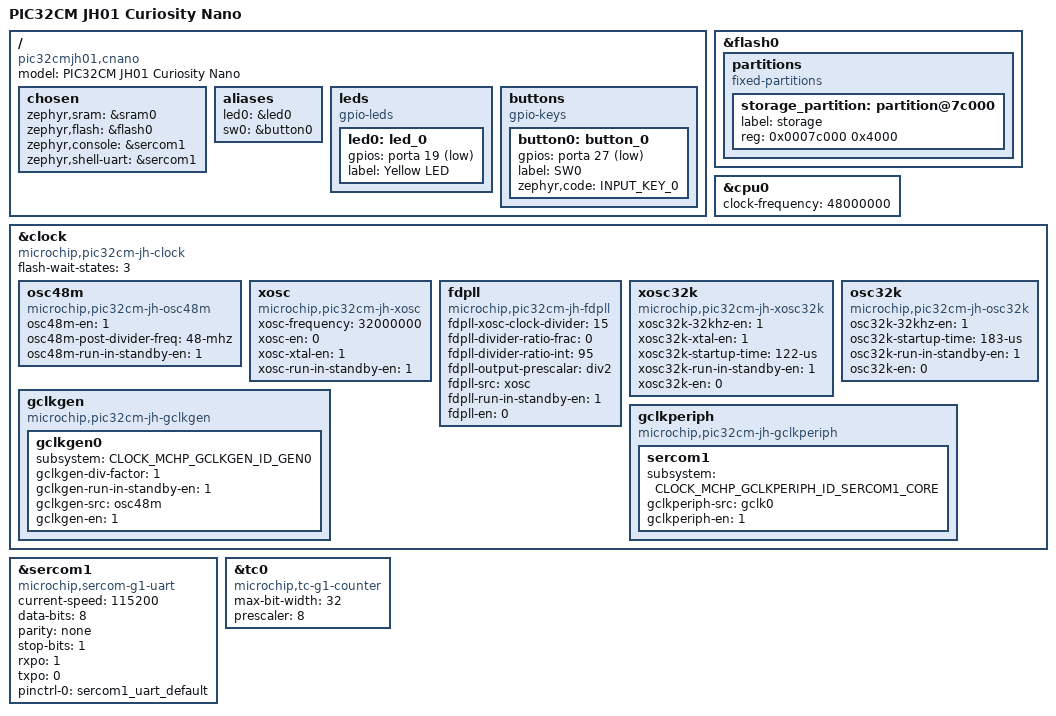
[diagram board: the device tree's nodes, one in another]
/*
 * Copyright (c) 2025-2026 Microchip Technology Inc.
 *
 * SPDX-License-Identifier: Apache-2.0
 */

/dts-v1/;
#include <microchip/pic32c/pic32cm_jh/pic32cm_jh01/pic32cm5164jh01048.dtsi>
#include <zephyr/dt-bindings/input/input-event-codes.h>
#include "pic32cm_jh01_cnano-pinctrl.dtsi"

/ {
	model = "PIC32CM JH01 Curiosity Nano";
	compatible = "pic32cmjh01,cnano", "microchip,pic32cm5164jh01048", "microchip,pic32cm";

	chosen {
		zephyr,sram = &sram0;
		zephyr,flash = &flash0;
		zephyr,console = &sercom1;
		zephyr,shell-uart = &sercom1;
	};

	aliases {
		led0 = &led0;
		sw0 = &button0;
	};

	leds {
		compatible = "gpio-leds";

		led0: led_0 {
			gpios = <&porta 19 GPIO_ACTIVE_LOW>;
			label = "Yellow LED";
		};
	};

	buttons {
		compatible = "gpio-keys";

		button0: button_0 {
			gpios = <&porta 27 (GPIO_PULL_UP | GPIO_ACTIVE_LOW)>;
			label = "SW0";
			zephyr,code = <INPUT_KEY_0>;
		};
	};
};

&flash0 {
	partitions {
		compatible = "fixed-partitions";
		#address-cells = <1>;
		#size-cells = <1>;

		storage_partition: partition@7c000 {
			label = "storage";
			reg = <0x0007c000 0x4000>;
		};
	};
};

&cpu0 {
	clock-frequency = <48000000>;
};

&clock {
	compatible = "microchip,pic32cm-jh-clock";

	/* If cpu sourced from osc48m, use 3 for CPU frequency above 24Mhz */
	flash-wait-states = <3>;

	osc48m: osc48m {
		compatible = "microchip,pic32cm-jh-osc48m";
		osc48m-en = <1>;
		osc48m-post-divider-freq = "48-mhz";
		osc48m-run-in-standby-en = <1>;
	};

	xosc: xosc {
		compatible = "microchip,pic32cm-jh-xosc";
		xosc-frequency = <32000000>;
		xosc-en = <0>;
		xosc-xtal-en = <1>;
		xosc-run-in-standby-en = <1>;
	};

	fdpll: fdpll {
		compatible = "microchip,pic32cm-jh-fdpll";
		fdpll-xosc-clock-divider = <15>;
		fdpll-divider-ratio-frac = <0>;
		fdpll-divider-ratio-int = <95>;
		fdpll-output-prescalar = "div2";
		fdpll-src = "xosc";
		fdpll-run-in-standby-en = <1>;
		fdpll-en = <0>;
	};

	xosc32k: xosc32k {
		compatible = "microchip,pic32cm-jh-xosc32k";
		xosc32k-32khz-en = <1>;
		xosc32k-xtal-en = <1>;
		xosc32k-startup-time = "122-us";
		xosc32k-run-in-standby-en = <1>;
		xosc32k-en = <0>;
	};

	osc32k: osc32k {
		compatible = "microchip,pic32cm-jh-osc32k";
		osc32k-32khz-en = <1>;
		osc32k-startup-time = "183-us";
		osc32k-run-in-standby-en = <1>;
		osc32k-en = <0>;
	};

	gclkgen: gclkgen {
		compatible = "microchip,pic32cm-jh-gclkgen";

		gclkgen0 {
			subsystem = <CLOCK_MCHP_GCLKGEN_ID_GEN0>;
			gclkgen-div-factor = <1>;
			gclkgen-run-in-standby-en = <1>;
			gclkgen-src = "osc48m";
			gclkgen-en = <1>;
		};
	};

	gclkperiph: gclkperiph {
		compatible = "microchip,pic32cm-jh-gclkperiph";
		#clock-cells = <1>;

		sercom1 {
			subsystem = <CLOCK_MCHP_GCLKPERIPH_ID_SERCOM1_CORE>;
			gclkperiph-src = "gclk0";
			gclkperiph-en = <1>;
		};
	};
};

&sercom1 {
	compatible = "microchip,sercom-g1-uart";
	current-speed = <115200>;
	data-bits = <8>;
	parity = "none";
	stop-bits = "1";
	rxpo = <1>;
	txpo = <0>;
	pinctrl-0 = <&sercom1_uart_default>;
	pinctrl-names = "default";
	status = "okay";
};

&tc0 {
	compatible = "microchip,tc-g1-counter";
	max-bit-width = <32>;
	prescaler = <8>;
	status = "okay";
};
